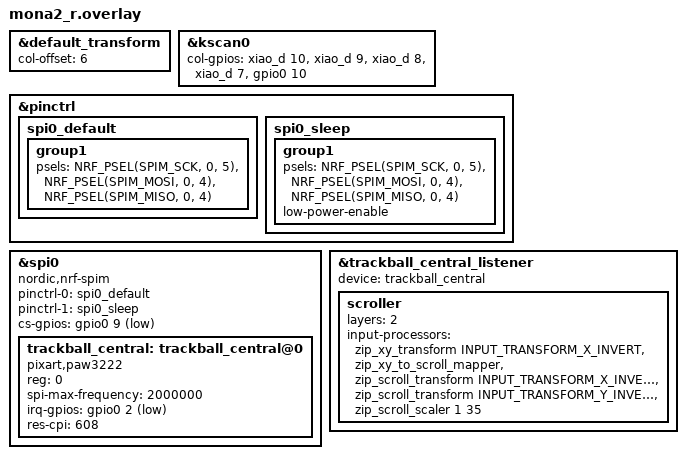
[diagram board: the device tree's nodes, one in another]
#include "mona2.dtsi"
#include <input/processors.dtsi>
#include <zephyr/dt-bindings/input/input-event-codes.h>

&default_transform {
    col-offset = <6>;
};

&kscan0 {
        col-gpios
            = <&xiao_d 10 GPIO_ACTIVE_HIGH>
            , <&xiao_d 9 GPIO_ACTIVE_HIGH> 
            , <&xiao_d 8 GPIO_ACTIVE_HIGH> 
            , <&xiao_d 7 GPIO_ACTIVE_HIGH> 
            , <&gpio0 10 GPIO_ACTIVE_HIGH>
            ;
};

&pinctrl {
    spi0_default: spi0_default {
        group1 {
            psels = <NRF_PSEL(SPIM_SCK, 0, 5)>,
                <NRF_PSEL(SPIM_MOSI, 0, 4)>,
                <NRF_PSEL(SPIM_MISO, 0, 4)>;
        };
    };
    spi0_sleep: spi0_sleep {
        group1 {
            psels = <NRF_PSEL(SPIM_SCK, 0, 5)>,
                <NRF_PSEL(SPIM_MOSI, 0, 4)>,
                <NRF_PSEL(SPIM_MISO, 0, 4)>;
            low-power-enable;
        };
    };
};

&spi0 {
    status = "okay";
    compatible = "nordic,nrf-spim";
    pinctrl-0 = <&spi0_default>;
    pinctrl-1 = <&spi0_sleep>;
    pinctrl-names = "default", "sleep";
    cs-gpios = <&gpio0 9 GPIO_ACTIVE_LOW>;  // P0.09 (CS) ※そのまま流用

    trackball_central: trackball_central@0 {
        status = "okay";
        compatible = "pixart,paw3222";              // ★変更: pmw3610 → paw3222
        reg = <0>;
        spi-max-frequency = <2000000>;
        irq-gpios = <&gpio0 2 (GPIO_ACTIVE_LOW | GPIO_PULL_UP)>; // P0.02 (MOTION) ※そのまま流用
        res-cpi = <608>;                            // ★変更: cpi → res-cpi (PAW3222用プロパティ名) 数値を下げると感度が下がる(デフォルト値800)
        // swap-xy / invert-x / invert-y / evt-type / x-input-code / y-input-code は
        // PAW3222ドライバに存在しないプロパティなので削除
    };
};

// Overrides for the input listener node
&trackball_central_listener {
    status = "okay";
    device = <&trackball_central>;
    /delete-property/ input-processors;   // ★親(mona2.dtsi)側のY軸反転設定を削除

    scroller {
        layers = <2>;       // ★ layer_2 でトラックボールがスクロールに切り替わる
        input-processors = 
            <&zip_xy_transform INPUT_TRANSFORM_X_INVERT>,
            <&zip_xy_to_scroll_mapper>,   // ← カーソル移動→スクロール変換
            <&zip_scroll_transform INPUT_TRANSFORM_X_INVERT>,
            <&zip_scroll_transform INPUT_TRANSFORM_Y_INVERT>,   // ★追加: 縦スクロール(上下)を反転
            <&zip_scroll_scaler 1 35>;     // ← スクロール量を1/5から調整
    };
};
